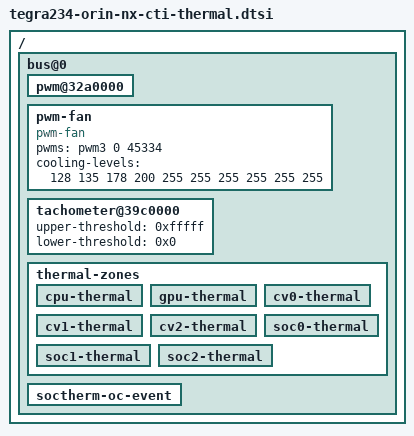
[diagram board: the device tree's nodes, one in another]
/*
 * Copyright (c) 2022, Connect Tech Inc.  All rights reserved.
 *
 * This program is free software; you can redistribute it and/or modify it
 * under the terms and conditions of the GNU General Public License,
 * version 2, as published by the Free Software Foundation.
 *
 * This program is distributed in the hope it will be useful, but WITHOUT
 * ANY WARRANTY; without even the implied warranty of MERCHANTABILITY or
 * FITNESS FOR A PARTICULAR PURPOSE.  See the GNU General Public License for
 * more details.
 *
 * You should have received a copy of the GNU General Public License
 * along with this program.  If not, see <http://www.gnu.org/licenses/>.
 */


#include <dt-bindings/gpio/tegra234-gpio.h>
#include <dt-bindings/pwm/pwm.h>

#include "nv-soc/tegra234-soc-thermal.dtsi"
#include "nv-soc/tegra234-soc-thermal-slowdown-corepair.dtsi"
#include "nv-soc/tegra234-soc-thermal-shutdown.dtsi"
#include "nv-soc/tegra234-soc-thermal-trip-event.dtsi"

/ {
    bus@0{
        //FAN PWM
        pwm@32a0000 {
            status = "okay";
        };

        pwm-fan {
            compatible = "pwm-fan";
            status = "okay";
            pwms = <&pwm3 0 45334>;
            #cooling-cells = <2>;
            cooling-levels = <128 135 178 200 255 255 255 255 255 255>;
        };


        tachometer@39c0000 {
            status = "okay";
            upper-threshold = <0xfffff>;
            lower-threshold = <0x0>;
        };

    thermal-zones {
        cpu-thermal {
            status = "okay";
        };

        gpu-thermal {
            status = "okay";
        };

        cv0-thermal {
            status = "okay";
        };

        cv1-thermal {
            status = "okay";
        };

        cv2-thermal {
            status = "okay";
        };

        soc0-thermal {
            status = "okay";
        };

        soc1-thermal {
            status = "okay";
        };

        soc2-thermal {
            status = "okay";
        };
    };
    soctherm-oc-event {
        status = "okay";
    };

    };

};
